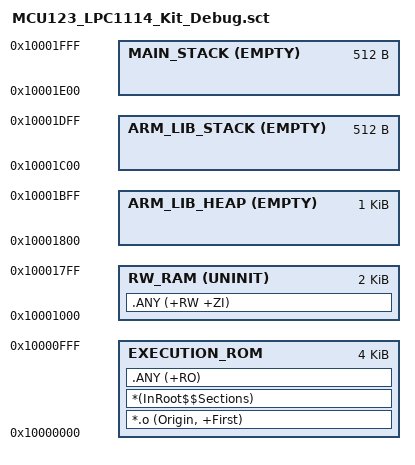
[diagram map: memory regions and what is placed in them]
;MCU123_LPC1114_Kit的连接描述文件

;装入区
LOAD_ROM 0x10000000 (1024 * 4)
{
	;执行区
	EXECUTION_ROM 0x10000000 (1024 * 4)
	{
		*.o (Origin, +First)
		*(InRoot$$Sections)
		.ANY (+RO)
	}
	
	;读写区
	RW_RAM (0x10000000 + 1024 * 4) UNINIT 2048
	{
		.ANY (+RW +ZI)
	}
	
	;运行时的堆区
	ARM_LIB_HEAP (0x10000000 + 1024 * 6) EMPTY 1024
	{
	}
	
	;运行时的栈区
	ARM_LIB_STACK (0x10000000 + 1024 * 7) EMPTY 512
	{
	}
	
	;主栈区
	MAIN_STACK (0x10000000 + 1024 * 7 + 512) EMPTY 512
	{
	}
}
